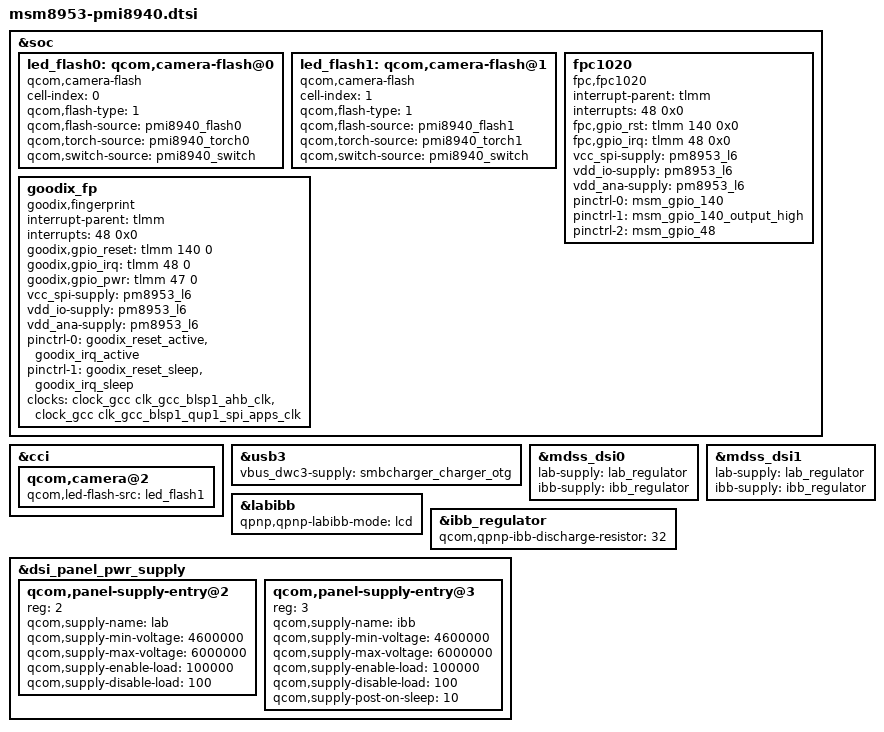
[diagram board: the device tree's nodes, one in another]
/*
 * Copyright (c) 2016-2017, The Linux Foundation. All rights reserved.
 * Copyright (C) 2018 XiaoMi, Inc.
 *
 * This program is free software; you can redistribute it and/or modify
 * it under the terms of the GNU General Public License version 2 and
 * only version 2 as published by the Free Software Foundation.
 *
 * This program is distributed in the hope that it will be useful,
 * but WITHOUT ANY WARRANTY; without even the implied warranty of
 * MERCHANTABILITY or FITNESS FOR A PARTICULAR PURPOSE.  See the
 * GNU General Public License for more details.
 */

#include "msm8953-audio-mtp.dtsi"

&soc {
	led_flash0: qcom,camera-flash@0 {
		cell-index = <0>;
		compatible = "qcom,camera-flash";
		qcom,flash-type = <1>;
		qcom,flash-source = <&pmi8940_flash0>;
		qcom,torch-source = <&pmi8940_torch0>;
		qcom,switch-source = <&pmi8940_switch>;
	};
	led_flash1: qcom,camera-flash@1 {
		cell-index = <1>;
		compatible = "qcom,camera-flash";
		qcom,flash-type = <1>;
		qcom,flash-source = <&pmi8940_flash1>;
		qcom,torch-source = <&pmi8940_torch1>;
		qcom,switch-source = <&pmi8940_switch>;
	};

	fpc1020 {
		status = "ok";
		compatible = "fpc,fpc1020";
		interrupt-parent = <&tlmm>;
		interrupts = <48 0x0>;
		fpc,gpio_rst    = <&tlmm 140 0x0>;
		fpc,gpio_irq    = <&tlmm 48 0x0>;

		vcc_spi-supply  = <&pm8953_l6>;
		vdd_io-supply   = <&pm8953_l6>;
		vdd_ana-supply  = <&pm8953_l6>;

		pinctrl-names = "fpc1020_reset_reset",
			"fpc1020_reset_active",
			"fpc1020_irq_active";

		pinctrl-0 = <&msm_gpio_140>;
		pinctrl-1 = <&msm_gpio_140_output_high>;
		pinctrl-2 = <&msm_gpio_48>;
		};

	goodix_fp {
		status = "ok";
		compatible = "goodix,fingerprint";
		interrupt-parent = <&tlmm>;
		interrupts = <48 0x0>;
		goodix,gpio_reset = <&tlmm 140 0>;
		goodix,gpio_irq = <&tlmm 48 0>;
		goodix,gpio_pwr = <&tlmm 47 0>;

		vcc_spi-supply  = <&pm8953_l6>;
		vdd_io-supply   = <&pm8953_l6>;
		vdd_ana-supply  = <&pm8953_l6>;

		pinctrl-0 = <&goodix_reset_active &goodix_irq_active>;
		pinctrl-1 = <&goodix_reset_sleep &goodix_irq_sleep>;
		clock-names = "iface_clk", "core_clk";

			clocks = <&clock_gcc clk_gcc_blsp1_ahb_clk>,
				<&clock_gcc clk_gcc_blsp1_qup1_spi_apps_clk>;
		};

};

&cci {
	qcom,camera@2 {
			qcom,led-flash-src = <&led_flash1>;
		};
};

&usb3 {
	vbus_dwc3-supply = <&smbcharger_charger_otg>;
};

&mdss_dsi0 {
	lab-supply = <&lab_regulator>;
	ibb-supply = <&ibb_regulator>;
};

&mdss_dsi1 {
	lab-supply = <&lab_regulator>;
	ibb-supply = <&ibb_regulator>;
};

&labibb {
	status = "ok";
	qpnp,qpnp-labibb-mode = "lcd";
};

&ibb_regulator {
	qcom,qpnp-ibb-discharge-resistor = <32>;
};

&dsi_panel_pwr_supply {
	qcom,panel-supply-entry@2 {
		reg = <2>;
		qcom,supply-name = "lab";
		qcom,supply-min-voltage = <4600000>;
		qcom,supply-max-voltage = <6000000>;
		qcom,supply-enable-load = <100000>;
		qcom,supply-disable-load = <100>;
	};

	qcom,panel-supply-entry@3 {
		reg = <3>;
		qcom,supply-name = "ibb";
		qcom,supply-min-voltage = <4600000>;
		qcom,supply-max-voltage = <6000000>;
		qcom,supply-enable-load = <100000>;
		qcom,supply-disable-load = <100>;
		qcom,supply-post-on-sleep = <10>;
	};
};
